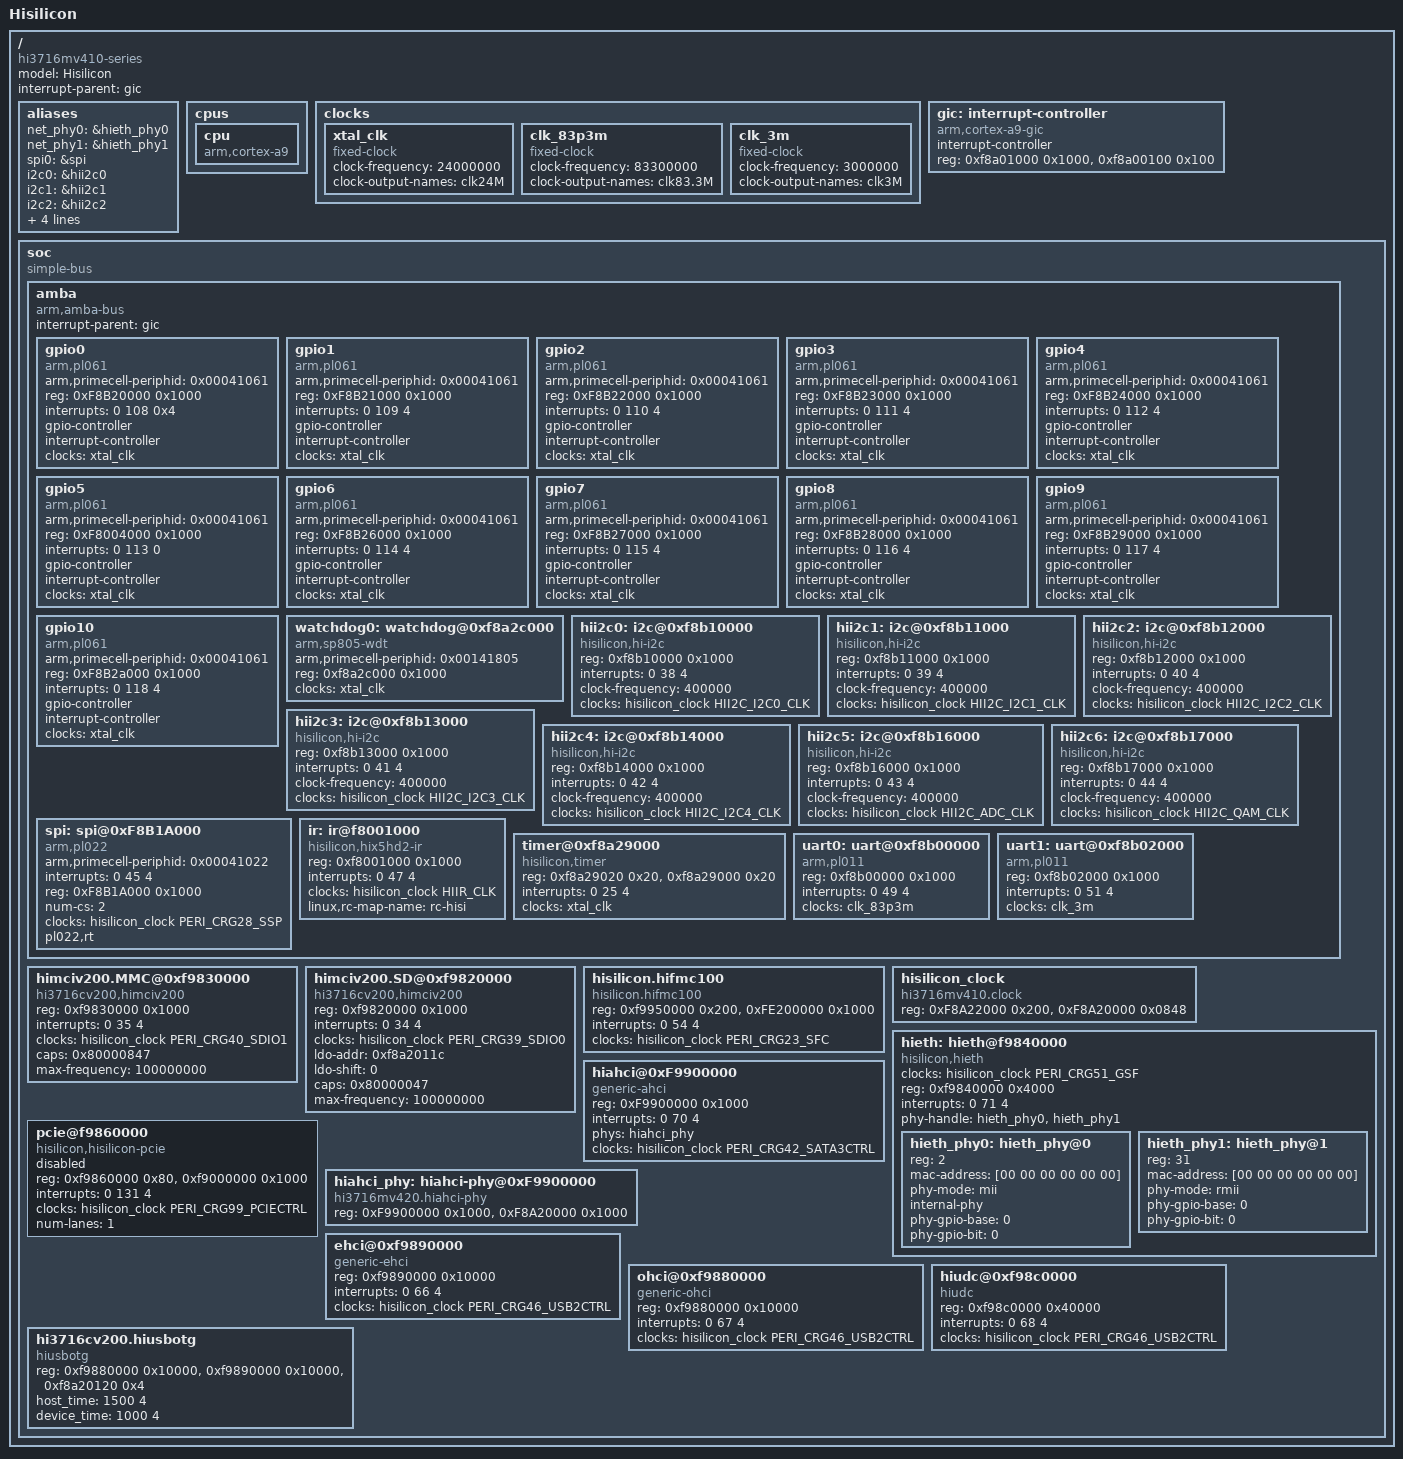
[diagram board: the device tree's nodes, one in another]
/dts-v1/;

#include <dt-bindings/clock/hi3716cv200-clock.h>

/ {
	model = "Hisilicon";
	compatible = "hi3716mv410-series";
	#address-cells = <1>;
	#size-cells = <1>;
	interrupt-parent = <&gic>;

	aliases {
		net_phy0 = &hieth_phy0;
		net_phy1 = &hieth_phy1;
		spi0=&spi;
		/* spi1=&spi_gpio; */
		i2c0=&hii2c0;
		i2c1=&hii2c1;
		i2c2=&hii2c2;
		i2c3=&hii2c3;
		i2c4=&hii2c4;
		i2c5=&hii2c5;
		i2c6=&hii2c6;
	};

	cpus {
		#address-cells = <1>;
		#size-cells = <0>;

		cpu {
			device_type = "cpu";
			compatible = "arm,cortex-a9";
		};
	};

	clocks {
		xtal_clk: xtal_clk {
			compatible = "fixed-clock";
			#clock-cells = <0>;
			clock-frequency = <24000000>;
			clock-output-names = "clk24M";
		};

		clk_83p3m: clk_83p3m {
			compatible = "fixed-clock";
			#clock-cells = <0>;
			clock-frequency = <83300000>;
			clock-output-names = "clk83.3M";
		};

		clk_3m: clk_3m{
			compatible = "fixed-clock";
			#clock-cells = <0>;
			clock-frequency = <3000000>;
			clock-output-names = "clk3M";
		};
	};

	gic: interrupt-controller {
		compatible = "arm,cortex-a9-gic";
		#interrupt-cells = <3>;
		#address-cells = <0>;
		interrupt-controller;
		reg = <0xf8a01000 0x1000>,
		      <0xf8a00100 0x100>;
	};

	soc {
		#address-cells = <1>;
		#size-cells = <1>;
		compatible = "simple-bus";
		device_type = "soc";
		ranges = <0x0 0x0 0xffffffff>;

		amba {
			compatible = "arm,amba-bus";
			#address-cells = <1>;
			#size-cells = <1>;
			interrupt-parent = <&gic>;
			ranges;

			gpio0: gpio0 {
				compatible = "arm,pl061", "arm,primecell";
				arm,primecell-periphid = <0x00041061>;
				reg = <0xF8B20000 0x1000>;
				interrupts = <0 108 0x4>;
				gpio-controller;
				#gpio-cells = <2>;
				interrupt-controller;
				#interrupt-cells = <2>;
				clocks = <&xtal_clk>;
				clock-names = "apb_pclk";
			};

			gpio1: gpio1 {
				compatible = "arm,pl061", "arm,primecell";
				arm,primecell-periphid = <0x00041061>;
				reg = <0xF8B21000 0x1000>;
				interrupts = <0 109 4>;
				gpio-controller;
				#gpio-cells = <2>;
				interrupt-controller;
				#interrupt-cells = <2>;
				clocks = <&xtal_clk>;
				clock-names = "apb_pclk";
			};

			gpio2: gpio2 {
				compatible = "arm,pl061", "arm,primecell";
				arm,primecell-periphid = <0x00041061>;
				reg = <0xF8B22000 0x1000>;
				interrupts = <0 110 4>;
				gpio-controller;
				#gpio-cells = <2>;
				interrupt-controller;
				#interrupt-cells = <2>;
				clocks = <&xtal_clk>;
				clock-names = "apb_pclk";
			};

			gpio3: gpio3 {
				compatible = "arm,pl061", "arm,primecell";
				arm,primecell-periphid = <0x00041061>;
				reg = <0xF8B23000 0x1000>;
				interrupts = <0 111 4>;
				gpio-controller;
				#gpio-cells = <2>;
				interrupt-controller;
				#interrupt-cells = <2>;
				clocks = <&xtal_clk>;
				clock-names = "apb_pclk";
			};

			gpio4: gpio4 {
				compatible = "arm,pl061", "arm,primecell";
				arm,primecell-periphid = <0x00041061>;
				reg = <0xF8B24000 0x1000>;
				interrupts = <0 112 4>;
				gpio-controller;
				#gpio-cells = <2>;
				interrupt-controller;
				#interrupt-cells = <2>;
				clocks = <&xtal_clk>;
				clock-names = "apb_pclk";
			};

			gpio5: gpio5 {
				compatible = "arm,pl061", "arm,primecell";
				arm,primecell-periphid = <0x00041061>;
				reg = <0xF8004000 0x1000>;
				interrupts = <0 113 0>;
				gpio-controller;
				#gpio-cells = <2>;
				interrupt-controller;
				#interrupt-cells = <2>;
				clocks = <&xtal_clk>;
				clock-names = "apb_pclk";
			};

			gpio6: gpio6 {
				compatible = "arm,pl061", "arm,primecell";
				arm,primecell-periphid = <0x00041061>;
				reg = <0xF8B26000 0x1000>;
				interrupts = <0 114 4>;
				gpio-controller;
				#gpio-cells = <2>;
				interrupt-controller;
				#interrupt-cells = <2>;
				clocks = <&xtal_clk>;
				clock-names = "apb_pclk";
			};

			gpio7: gpio7 {
				compatible = "arm,pl061", "arm,primecell";
				arm,primecell-periphid = <0x00041061>;
				reg = <0xF8B27000 0x1000>;
				interrupts = <0 115 4>;
				gpio-controller;
				#gpio-cells = <2>;
				interrupt-controller;
				#interrupt-cells = <2>;
				clocks = <&xtal_clk>;
				clock-names = "apb_pclk";
			};

			gpio8: gpio8 {
				compatible = "arm,pl061", "arm,primecell";
				arm,primecell-periphid = <0x00041061>;
				reg = <0xF8B28000 0x1000>;
				interrupts = <0 116 4>;
				gpio-controller;
				#gpio-cells = <2>;
				interrupt-controller;
				#interrupt-cells = <2>;
				clocks = <&xtal_clk>;
				clock-names = "apb_pclk";
			};

			gpio9: gpio9 {
				compatible = "arm,pl061", "arm,primecell";
				arm,primecell-periphid = <0x00041061>;
				reg = <0xF8B29000 0x1000>;
				interrupts = <0 117 4>;
				gpio-controller;
				#gpio-cells = <2>;
				interrupt-controller;
				#interrupt-cells = <2>;
				clocks = <&xtal_clk>;
				clock-names = "apb_pclk";
			};

			gpio10: gpio10 {
				compatible = "arm,pl061", "arm,primecell";
				arm,primecell-periphid = <0x00041061>;
				reg = <0xF8B2a000 0x1000>;
				interrupts = <0 118 4>;
				gpio-controller;
				#gpio-cells = <2>;
				interrupt-controller;
				#interrupt-cells = <2>;
				clocks = <&xtal_clk>;
				clock-names = "apb_pclk";
			};

			/*
			 * Used for clocksource and local timer
			 */
			watchdog0: watchdog@0xf8a2c000 {
				compatible = "arm,sp805-wdt", "arm,primecell";
				arm,primecell-periphid = <0x00141805>;
				reg = <0xf8a2c000 0x1000>;
				clocks = <&xtal_clk>;
				clock-names = "apb_pclk";
			};
			
			hii2c0:i2c@0xf8b10000 {
				compatible = "hisilicon,hi-i2c";
				reg = <0xf8b10000 0x1000>;
				interrupts = <0 38 4>;
				clock-frequency = <400000>;
				clocks = <&hisilicon_clock HII2C_I2C0_CLK>;
				clock-names = "apb_pclk";
				#address-cells = <1>;
				#size-cells = <0>;
			};

			hii2c1:i2c@0xf8b11000 {
				compatible = "hisilicon,hi-i2c";
				reg = <0xf8b11000 0x1000>;
				interrupts = <0 39 4>;
				clock-frequency = <400000>;
				clocks = <&hisilicon_clock HII2C_I2C1_CLK>;
				clock-names = "apb_pclk";
				#address-cells = <1>;
				#size-cells = <0>;
			};

			hii2c2:i2c@0xf8b12000 {
				compatible = "hisilicon,hi-i2c";
				reg = <0xf8b12000 0x1000>;
				interrupts = <0 40 4>;
				clock-frequency = <400000>;
				clocks = <&hisilicon_clock HII2C_I2C2_CLK>;
				clock-names = "apb_pclk";
				#address-cells = <1>;
				#size-cells = <0>;
			};
			
			hii2c3:i2c@0xf8b13000 {
				compatible = "hisilicon,hi-i2c";
				reg = <0xf8b13000 0x1000>;
				interrupts = <0 41 4>;
				clock-frequency = <400000>;
				clocks = <&hisilicon_clock HII2C_I2C3_CLK>;
				clock-names = "apb_pclk";
				#address-cells = <1>;
				#size-cells = <0>;
			};

			hii2c4:i2c@0xf8b14000 {
				compatible = "hisilicon,hi-i2c";
				reg = <0xf8b14000 0x1000>;
				interrupts = <0 42 4>;
				clock-frequency = <400000>;
				clocks = <&hisilicon_clock HII2C_I2C4_CLK>;
				clock-names = "apb_pclk";
				#address-cells = <1>;
				#size-cells = <0>;
			};
			
			hii2c5:i2c@0xf8b16000 {
				compatible = "hisilicon,hi-i2c";
				reg = <0xf8b16000 0x1000>;
				interrupts = <0 43 4>;
				clock-frequency = <400000>;
				clocks = <&hisilicon_clock HII2C_ADC_CLK>;
				clock-names = "apb_pclk";
				#address-cells = <1>;
				#size-cells = <0>;
			};

			hii2c6:i2c@0xf8b17000 {
				compatible = "hisilicon,hi-i2c";
				reg = <0xf8b17000 0x1000>;
				interrupts = <0 44 4>;
				clock-frequency = <400000>;
				clocks = <&hisilicon_clock HII2C_QAM_CLK>;
				clock-names = "apb_pclk";
				#address-cells = <1>;
				#size-cells = <0>;
			};
			spi:spi@0xF8B1A000 {
				compatible = "arm,pl022", "arm,primecell";
				arm,primecell-periphid = <0x00041022>;
				interrupts = <0 45 4>;
				reg = <0xF8B1A000 0x1000>;
				num-cs = <2>;
				#address-cells = <1>;
				#size-cells = <0>;
				clocks = <&hisilicon_clock PERI_CRG28_SSP>;
				clock-names = "apb_pclk";
				pl022,rt;

				/* userspace spi interface
				 * parse by of_register_spi_devices function
				 */
				/*spidev@0 {
				*	compatible = "rohm,dh2228fv";
				*	reg = <1>;
				* 	spi-max-frequency = <16000000>;
				* };
				*/
			};

			/*
			 *spi_gpio: spi-gpio {
			 *	compatible = "spi-gpio";
			 *	#address-cells = <1>;
			 *	#size-cells = <0>;
			 *	gpio-sck = <&gpio1 1 0>;
			 *	gpio-miso = <&gpio1 3 0>;
			 *	gpio-mosi = <&gpio1 2 0>;
			 *	num-chipselects = <1>;
			 *	cs-gpios = <&gpio1 4 1>;
			 *};
			 */

			ir: ir@f8001000 {
				compatible = "hisilicon,hix5hd2-ir";
				reg = <0xf8001000 0x1000>;
				interrupts = <0 47 4>;
				clocks = <&hisilicon_clock HIIR_CLK>;
				linux,rc-map-name = "rc-hisi";
			};

			timer@0xf8a29000 {
				compatible = "hisilicon,timer";
				reg = <0xf8a29020 0x20>, /* clocksource */
				      <0xf8a29000 0x20>;
				interrupts = <0 25 4>;
				clocks = <&xtal_clk>;
				clock-names = "apb_pclk";
			};

			uart0: uart@0xf8b00000 {
				compatible = "arm,pl011", "arm,primecell";
				reg = <0xf8b00000 0x1000>;
				interrupts = <0 49 4>;
				clocks = <&clk_83p3m>;
				clock-names = "apb_pclk";
			};

			uart1: uart@0xf8b02000 {
				compatible = "arm,pl011", "arm,primecell";
				reg = <0xf8b02000 0x1000>;
				interrupts = <0 51 4>;
				clocks = <&clk_3m>;
				clock-names = "apb_pclk";
			};
		};

		himciv200.MMC@0xf9830000 {
			compatible = "hi3716cv200,himciv200";
			reg = <0xf9830000 0x1000>;
			interrupts = <0 35 4>;

			clocks = <&hisilicon_clock PERI_CRG40_SDIO1>;
			clock-names = "clk";

			caps = <0x80000847>;
			max-frequency = <100000000>;
		};

		himciv200.SD@0xf9820000 {
			compatible = "hi3716cv200,himciv200";
			reg = <0xf9820000 0x1000>;
			interrupts = <0 34 4>;

			clocks = <&hisilicon_clock PERI_CRG39_SDIO0>;
			clock-names = "clk";

			ldo-addr  = <0xf8a2011c>;
			ldo-shift = <0>;

			caps = <0x80000047>;
			max-frequency = <100000000>;
		};

		hisilicon.hifmc100 {
			compatible = "hisilicon.hifmc100";
			reg = <0xf9950000 0x200>,<0xFE200000 0x1000>;
			interrupts = <0 54 4>;

			clocks = <&hisilicon_clock PERI_CRG23_SFC>;
			clock-names = "clk";
		};

		hisilicon_clock: hisilicon_clock {
			compatible = "hi3716mv410.clock";
			reg = <0xF8A22000 0x200>, <0xF8A20000 0x0848>;
			#clock-cells = <1>;
		};

		hieth: hieth@f9840000 {
			compatible = "hisilicon,hieth";
			clocks = <&hisilicon_clock PERI_CRG51_GSF>;
			clock-names = "clk";
			reg = <0xf9840000 0x4000>;
			interrupts = <0 71 4>;
			phy-handle = <&hieth_phy0 &hieth_phy1>;
			#address-cells = <1>;
			#size-cells = <0>;

			hieth_phy0: hieth_phy@0 {
				reg = <2>;
				mac-address = [00 00 00 00 00 00];
				phy-mode = "mii";
				internal-phy;
				phy-gpio-base = <0>;
				phy-gpio-bit = <0>;
			};

			hieth_phy1: hieth_phy@1{
				reg = <31>;
				mac-address = [00 00 00 00 00 00];
				phy-mode = "rmii";
				phy-gpio-base = <0>;
				phy-gpio-bit = <0>;
			};
		};

		/* hiahci@0xF9900000 and pcie@f9860000 , select 1 of 2 */
		hiahci@0xF9900000 {
			compatible = "generic-ahci";
			reg = <0xF9900000 0x1000>;
			interrupts = <0 70 4>;

			phys = <&hiahci_phy>;
			phy-names = "sata-phy";

			clocks = <&hisilicon_clock PERI_CRG42_SATA3CTRL>;
			clock-names = "clk";
			status = "okay";
		};

		pcie@f9860000 {
			compatible = "hisilicon,hisilicon-pcie","snps,dw-pcie";
			reg = <0xf9860000 0x80>,<0xf9000000 0x1000>;
			interrupts = <0 131 4>;

			clocks = <&hisilicon_clock PERI_CRG99_PCIECTRL>;
			clock-names = "clk";

			#address-cells = <3>;
			#size-cells = <2>;
			device_type = "pci";
			ranges=<0x00000800 0 0xc8100000 0xc8100000 0 0x00100000
					0x81000000 0 0xc8000000 0xc8000000 0 0x00100000
					0x82000000 0 0xc0000000 0xc0000000 0 0x08000000>;
			num-lanes = <1>;
			status = "disabled";
		};

		hiahci_phy: hiahci-phy@0xF9900000 {
			compatible = "hi3716mv420.hiahci-phy";
			reg = <0xF9900000 0x1000>,<0xF8A20000 0x1000>;
			#phy-cells = <0>;
		};

		ehci@0xf9890000 {
			compatible = "generic-ehci";
			reg = <0xf9890000 0x10000>;
			interrupts = <0 66 4>;

			clocks = <&hisilicon_clock PERI_CRG46_USB2CTRL>;
			clock-names = "clk";
		};

		ohci@0xf9880000 {
			compatible = "generic-ohci";
			reg = <0xf9880000 0x10000>;
			interrupts = <0 67 4>;

			clocks = <&hisilicon_clock PERI_CRG46_USB2CTRL>;
			clock-names = "clk";
		};

		hiudc@0xf98c0000 {
			compatible = "hiudc";
			reg = <0xf98c0000 0x40000>;
			interrupts = <0 68 4>;

			clocks = <&hisilicon_clock PERI_CRG46_USB2CTRL>;
			clock-names = "clk";
		};

		hi3716cv200.hiusbotg {
			compatible = "hiusbotg";
			reg = <0xf9880000 0x10000>,<0xf9890000 0x10000>,<0xf8a20120 0x4>;
			host_time = <1500 4>;
			device_time = <1000 4>;
		};
	};
};
